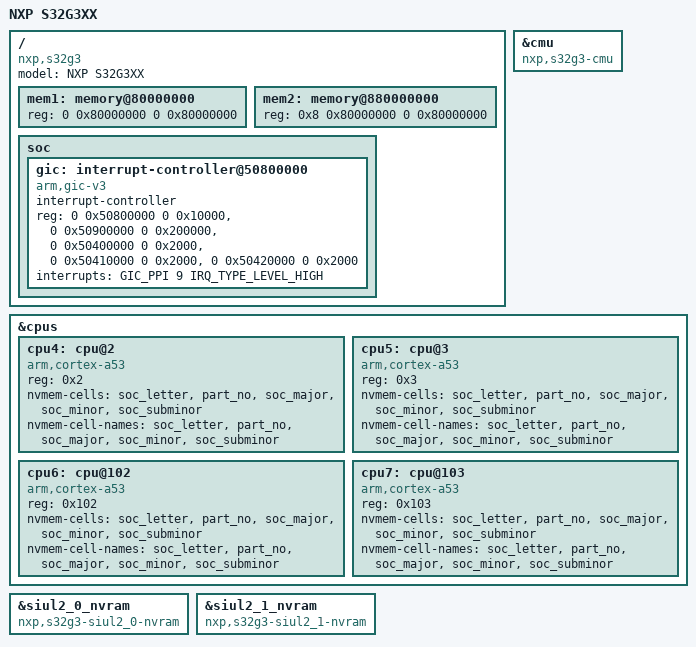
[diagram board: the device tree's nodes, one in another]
// SPDX-License-Identifier: GPL-2.0+
/*
 * Copyright 2021-2022 NXP
 *
 * This program is free software; you can redistribute it and/or modify
 * it under the terms of the GNU General Public License as published by
 * the Free Software Foundation; either version 2 of the License, or
 * (at your option) any later version.
 */

/delete-node/ &gic;
/ {
	model = "NXP S32G3XX";
	compatible = "nxp,s32g3";

	mem1: memory@80000000 {
		device_type = "memory";
		reg = <0 0x80000000 0 0x80000000>;
	};

	mem2: memory@880000000 {
		device_type = "memory";
		reg = <0x8 0x80000000 0 0x80000000>;
	};

	soc {
		gic: interrupt-controller@50800000 {
			compatible = "arm,gic-v3";
			#interrupt-cells = <3>;
			#address-cells = <2>;
			#size-cells = <2>;
			interrupt-controller;
			reg = <0 0x50800000 0 0x10000>, /* GIC Dist */
			      <0 0x50900000 0 0x200000>, /* GICR (RD_base + SGI_base) */
			      <0 0x50400000 0 0x2000>, /* GICC */
			      <0 0x50410000 0 0x2000>, /* GICH */
			      <0 0x50420000 0 0x2000>; /* GICV */
			interrupts = <GIC_PPI 9 IRQ_TYPE_LEVEL_HIGH>;
		};
	};
};

&cmu {
	compatible = "nxp,s32g3-cmu";
};

&cpus {
	cpu4: cpu@2 {
		device_type = "cpu";
		compatible = "arm,cortex-a53";
		reg = <0x2>;

		nvmem-cells = <&soc_letter>, <&part_no>,
			<&soc_major>, <&soc_minor>, <&soc_subminor>;
		nvmem-cell-names = "soc_letter", "part_no",
			"soc_major", "soc_minor", "soc_subminor";
	};

	cpu5: cpu@3 {
		device_type = "cpu";
		compatible = "arm,cortex-a53";
		reg = <0x3>;

		nvmem-cells = <&soc_letter>, <&part_no>,
			<&soc_major>, <&soc_minor>, <&soc_subminor>;
		nvmem-cell-names = "soc_letter", "part_no",
			"soc_major", "soc_minor", "soc_subminor";
	};

	cpu6: cpu@102 {
		device_type = "cpu";
		compatible = "arm,cortex-a53";
		reg = <0x102>;

		nvmem-cells = <&soc_letter>, <&part_no>,
			<&soc_major>, <&soc_minor>, <&soc_subminor>;
		nvmem-cell-names = "soc_letter", "part_no",
			"soc_major", "soc_minor", "soc_subminor";
	};

	cpu7: cpu@103 {
		device_type = "cpu";
		compatible = "arm,cortex-a53";
		reg = <0x103>;

		nvmem-cells = <&soc_letter>, <&part_no>,
			<&soc_major>, <&soc_minor>, <&soc_subminor>;
		nvmem-cell-names = "soc_letter", "part_no",
			"soc_major", "soc_minor", "soc_subminor";
	};
};

&siul2_0_nvram {
	compatible = "nxp,s32g3-siul2_0-nvram";
};

&siul2_1_nvram {
	compatible = "nxp,s32g3-siul2_1-nvram";
};
